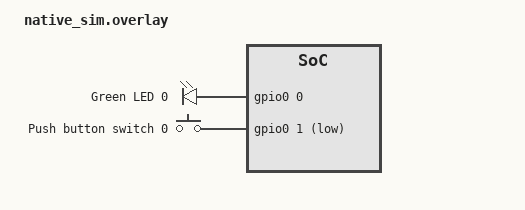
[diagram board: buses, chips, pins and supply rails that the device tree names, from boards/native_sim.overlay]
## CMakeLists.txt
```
cmake_minimum_required(VERSION 3.20.0)

find_package(Zephyr REQUIRED HINTS $ENV{ZEPHYR_BASE})
project(mw_test_app)
zephyr_compile_definitions(PROJECT_NAME=${PROJECT_NAME})

target_sources(app PRIVATE src/main.c)

# Include source directory
target_include_directories(app PRIVATE src)
target_include_directories(app PRIVATE src/common)

# Include files that are common for all modules
add_subdirectory(src/common)

# # Include modules
add_subdirectory(src/modules/button)
add_subdirectory(src/modules/led)
add_subdirectory(src/modules/uart)
```

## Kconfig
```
# Copyright (c) 2021 Nordic Semiconductor ASA
# SPDX-License-Identifier: Apache-2.0
#
# This file is the application Kconfig entry point. All application Kconfig
# options can be defined here or included via other application Kconfig files.
# You can browse these options using the west targets menuconfig (terminal) or
# guiconfig (GUI).

menu "Zephyr"
source "Kconfig.zephyr"
endmenu

module = APP
module-str = APP
source "subsys/logging/Kconfig.template.log_config"

rsource "src/modules/button/Kconfig.button"
rsource "src/modules/led/Kconfig.led"
rsource "src/modules/uart/Kconfig.uart"
```

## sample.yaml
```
# This file is provided so that the application can be compiled using Twister,
# the Zephyr testing tool. In this file, multiple combinations can be specified,
# so that you can easily test all of them locally or in CI.
sample:
  description: Example application
  name: example-application 
common:
  build_only: true
  integration_platforms:
    - custom_plank
    - nucleo_f302r8
    - nrf52840dk_nrf52840
tests:
  app.default: {}
  app.debug:
    extra_overlay_confs:
      - debug.conf
```

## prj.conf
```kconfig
# Copyright (c) 2021 Nordic Semiconductor ASA
# SPDX-License-Identifier: Apache-2.0
#
# This file contains selected Kconfig options for the application.
CONFIG_ASSERT=y

CONFIG_LOG=y
CONFIG_BOOT_BANNER=n
CONFIG_APP_LOG_LEVEL_INF=y
CONFIG_APP_BUTTON_LOG_LEVEL_INF=y
CONFIG_APP_LED_LOG_LEVEL_INF=y
CONFIG_APP_UART_LOG_LEVEL_INF=y

CONFIG_ZBUS=y
CONFIG_ZBUS_LOG_LEVEL_INF=y
CONFIG_ZBUS_RUNTIME_OBSERVERS=y

CONFIG_ZBUS_CHANNEL_NAME=y
CONFIG_ZBUS_OBSERVER_NAME=y

CONFIG_GPIO=y

CONFIG_SERIAL=y
CONFIG_UART_ASYNC_API=y

CONFIG_SHELL=y
CONFIG_LOG_CMDS=y
CONFIG_DEVICE_SHELL=y
CONFIG_GPIO_SHELL=y

# Task Watchdog
CONFIG_TASK_WDT=y
CONFIG_TASK_WDT_CHANNELS=5
CONFIG_TASK_WDT_MIN_TIMEOUT=10000

# Device power management
CONFIG_PM_DEVICE=y

#Debug
CONFIG_DEBUG=y
CONFIG_DEBUG_OPTIMIZATIONS=y
CONFIG_TRAP_UNALIGNED_ACCESS=y
# Note (sidmodi): CONFIG_NO_OPTIMIZATIONS would cause LOG hardfaults on the Nucleo-F401RE board - might have to investigate
```

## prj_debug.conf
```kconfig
# Copyright (c) 2021 Nordic Semiconductor ASA
# SPDX-License-Identifier: Apache-2.0
#
# This file contains selected Kconfig options for the application.
CONFIG_LOG=y
CONFIG_ASSERT=y
CONFIG_BOOT_BANNER=n

CONFIG_ZBUS=y
CONFIG_ZBUS_LOG_LEVEL_INF=y
CONFIG_ZBUS_RUNTIME_OBSERVERS=y

CONFIG_MP_MAX_NUM_CPUS=1
CONFIG_ZBUS_CHANNEL_NAME=y
CONFIG_ZBUS_OBSERVER_NAME=y

CONFIG_EMUL=y
CONFIG_GPIO=y
CONFIG_GPIO_EMUL=y

CONFIG_DEBUG_THREAD_INFO=y
CONFIG_THREAD_NAME=y
CONFIG_THREAD_STACK_INFO=y
CONFIG_THREAD_RUNTIME_STATS=y
CONFIG_THREAD_RUNTIME_STATS_USE_TIMING_FUNCTIONS=y
```

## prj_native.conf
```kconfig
# Copyright (c) 2021 Nordic Semiconductor ASA
# SPDX-License-Identifier: Apache-2.0
#
# This file contains selected Kconfig options for the application.
CONFIG_LOG=y
CONFIG_ASSERT=y
CONFIG_BOOT_BANNER=n

CONFIG_ZBUS=y
CONFIG_ZBUS_LOG_LEVEL_INF=y
CONFIG_ZBUS_RUNTIME_OBSERVERS=y

CONFIG_MP_MAX_NUM_CPUS=1
CONFIG_ZBUS_CHANNEL_NAME=y
CONFIG_ZBUS_OBSERVER_NAME=y

CONFIG_EMUL=y
CONFIG_GPIO=y
CONFIG_GPIO_EMUL=y
```

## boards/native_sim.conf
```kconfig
CONFIG_EMUL=y
CONFIG_GPIO_EMUL=y
CONFIG_UART_EMUL=y

CONFIG_UART_NATIVE_POSIX=y
CONFIG_NATIVE_UART_0_ON_OWN_PTY=y
CONFIG_LOG_BACKEND_NATIVE_POSIX=n

CONFIG_SHELL_BACKENDS=y
CONFIG_SHELL_BACKEND_SERIAL=y
CONFIG_SHELL_BACKEND_SERIAL_INTERRUPT_DRIVEN=n # https://github.com/zephyrproject-rtos/zephyr/issues/81459
CONFIG_SHELL_LOG_BACKEND=y
CONFIG_LOG_CMDS=y
CONFIG_DEVICE_SHELL=y
CONFIG_GPIO_SHELL=y

CONFIG_ASAN=y
CONFIG_UBSAN=y
```

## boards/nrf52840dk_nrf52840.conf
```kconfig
CONFIG_UART_1_ASYNC=y
CONFIG_UART_1_INTERRUPT_DRIVEN=n

# https://devzone.nordicsemi.com/f/nordic-q-a/92325/use-shell-over-uart-and-uart-async-api-on-nrf52840
CONFIG_UART_0_INTERRUPT_DRIVEN=y
CONFIG_UART_0_ASYNC=n
```

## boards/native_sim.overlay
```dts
/*
 * Copyright (c) 2021 Nordic Semiconductor ASA
 * SPDX-License-Identifier: Apache-2.0
 */

/* This devicetree overlay file will be automatically picked by the Zephyr
 * build system when building the sample for the nrf52840dk board. It shows
 * how the example-application can be built on sample boards already provided
 * by Zephyr.
 */

/ {
    leds {
		compatible = "gpio-leds";
		led0: led_0 {
			gpios = <&gpio0 0 GPIO_ACTIVE_HIGH>;
			label = "Green LED 0";
		};
	};

    buttons {
		compatible = "gpio-keys";
		button0: button_0 {
			gpios = <&gpio0 1 (GPIO_PULL_UP | GPIO_ACTIVE_LOW)>;
			label = "Push button switch 0";
		};
	};

    aliases {
		led0 = &led0;
		sw0 = &button0;
	};
};

&gpio0 {
	status = "okay";
	ngpios = <2>;
};
```

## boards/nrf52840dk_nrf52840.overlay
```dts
/*
 * Copyright (c) 2021 Nordic Semiconductor ASA
 * SPDX-License-Identifier: Apache-2.0
 */

/* This devicetree overlay file will be automatically picked by the Zephyr
 * build system when building the sample for the nrf52840dk board. It shows
 * how the example-application can be built on sample boards already provided
 * by Zephyr.
 */

/ {
    aliases {
		datauart = &uart1;
	};
};

&gpio0 {
	status = "okay";
};

&uart1 {
	status = "okay";
};
```

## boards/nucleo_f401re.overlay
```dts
/*
 * Copyright (c) 2021 Nordic Semiconductor ASA
 * SPDX-License-Identifier: Apache-2.0
 */

/* This devicetree overlay file will be automatically picked by the Zephyr
 * build system when building the sample for the nrf52840dk board. It shows
 * how the example-application can be built on sample boards already provided
 * by Zephyr.
 */

/ {
    aliases {
		datauart = &usart1;
	};

	gpio_keys {
		compatible = "gpio-keys";
		debounce-interval-ms = <100>;
	};
};

&gpioa {
	status = "okay";
};

&gpioc {
	status = "okay";
};

&dma1 {
	status = "okay";
};

&dma2 {
	status = "okay";
};
```

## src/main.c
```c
/*
 * Copyright (c) 2022 Rodrigo Peixoto <rodrigopex@gmail.com>
 * SPDX-License-Identifier: Apache-2.0
 */

#include <stdint.h>

#include <zephyr/kernel.h>
#include <zephyr/logging/log.h>
#include <zephyr/zbus/zbus.h>

#include "app_version.h"

LOG_MODULE_REGISTER( app, CONFIG_APP_LOG_LEVEL );

static bool print_channel_data_iterator( const struct zbus_channel *chan, void *user_data )
{
    int *count = user_data;

    LOG_INF( "%d - Channel %s:", *count, zbus_chan_name( chan ) );
    LOG_INF( "      Message size: %d", zbus_chan_msg_size( chan ) );
    LOG_INF( "      Observers:" );

    ++( *count );

    struct zbus_channel_observation *observation;

    for( int16_t i = chan->data->observers_start_idx, limit = chan->data->observers_end_idx; i < limit; ++i )
    {
        STRUCT_SECTION_GET( zbus_channel_observation, i, &observation );

        __ASSERT( observation != NULL, "observation must be not NULL" );

        LOG_INF( "      - %s", observation->obs->name );
    }

    struct zbus_observer_node *obs_nd, *tmp;

    SYS_SLIST_FOR_EACH_CONTAINER_SAFE( &chan->data->observers, obs_nd, tmp, node )
    {
        LOG_INF( "      - %s", obs_nd->obs->name );
    }

    return true;
}

static bool print_observer_data_iterator( const struct zbus_observer *obs, void *user_data )
{
    int *count = user_data;

    LOG_INF( "%d - %s %s", *count, obs->type == ZBUS_OBSERVER_LISTENER_TYPE ? "Listener" : "Subscriber", zbus_obs_name( obs ) );

    ++( *count );

    return true;
}

#include <zephyr/task_wdt/task_wdt.h>
static int watchdog_init( void )
{
    __ASSERT( ( task_wdt_init( NULL ) == 0 ), "Task watchdog init failure" );
    return 0;
}

int main( void )
{
    int count = 0;

    LOG_INF( "App version: %s-%s", APP_VERSION_STRING, STRINGIFY( APP_BUILD_VERSION ) );

    LOG_INF( "Channel list:" );
    zbus_iterate_over_channels_with_user_data( print_channel_data_iterator, &count );

    count = 0;

    LOG_INF( "Observers list:" );
    zbus_iterate_over_observers_with_user_data( print_observer_data_iterator, &count );

    return 0;
}

SYS_INIT( watchdog_init, POST_KERNEL, 0 );
```
